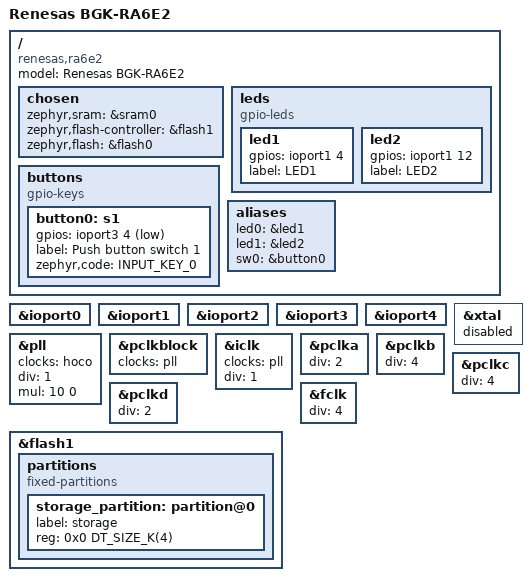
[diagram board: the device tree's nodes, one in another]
/dts-v1/;

#include <renesas/ra/ra6/r7fa6e2bb3cfm.dtsi>
#include <zephyr/dt-bindings/gpio/gpio.h>
#include <zephyr/dt-bindings/input/input-event-codes.h>
#include "bgk_ra6e2-pinctrl.dtsi"

/ {
	model = "Renesas BGK-RA6E2";
	compatible = "renesas,ra6e2", "renesas,ra";

    chosen {
        zephyr,sram = &sram0;
        zephyr,flash-controller = &flash1;
        zephyr,flash = &flash0;
    };

    leds {
        compatible = "gpio-leds";

        led1: led1 {
			gpios = <&ioport1 4 GPIO_ACTIVE_HIGH>;
			label = "LED1";
		};

		led2: led2 {
			gpios = <&ioport1 12 GPIO_ACTIVE_HIGH>;
			label = "LED2";
		};
    };

    buttons {
        compatible = "gpio-keys";

        button0: s1 {
			gpios = <&ioport3 4 (GPIO_PULL_UP | GPIO_ACTIVE_LOW)>;
			label = "Push button switch 1";
			zephyr,code = <INPUT_KEY_0>;
		};
    };

    aliases {
        led0 = &led1;
        led1 = &led2;
        sw0 = &button0;
    };
};

&ioport0 {
	status = "okay";
};

&ioport1 {
	status = "okay";
};

&ioport2 {
	status = "okay";
};

&ioport3 {
	status = "okay";
};

&ioport4 {
	status = "okay";
};

&xtal {
	status = "disabled";
};

&pll {
	clocks = <&hoco>;
	div = <1>;
	mul = <10 0>;
	status = "okay";
};

&pclkblock {
    clocks = <&pll>;
};

&iclk {
    clocks = <&pll>;
    div = <1>;
};

&pclka {
    div = <2>;
};

&pclkb {
    div = <4>;
};

&pclkc {
    div = <4>;
};

&pclkd {
    div = <2>;
};

&fclk {
    div = <4>;
};

&flash1 {
	partitions {
		compatible = "fixed-partitions";
		#address-cells = <1>;
		#size-cells = <1>;

		storage_partition: partition@0 {
			label = "storage";
			reg = <0x0 DT_SIZE_K(4)>;
		};
	};
};
